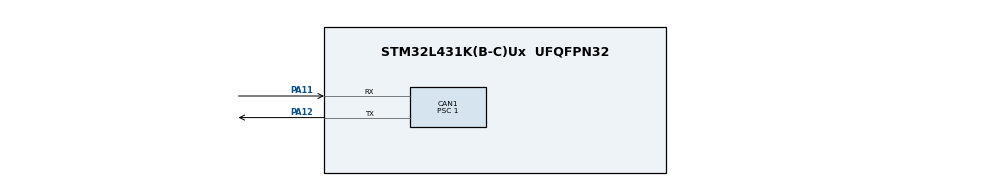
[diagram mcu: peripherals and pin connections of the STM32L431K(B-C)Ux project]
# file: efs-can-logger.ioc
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CAN1.BS1=CAN_BS1_6TQ
CAN1.CalculateBaudRate=500000
CAN1.CalculateTimeBit=2000
CAN1.CalculateTimeQuantum=250.0
CAN1.Prescaler=1
CAN1.SJW=CAN_SJW_2TQ
Mcu.Family=STM32L4
Mcu.Name=STM32L431K(B-C)Ux
Mcu.Package=UFQFPN32
NVIC.CAN1_RX0_IRQn=true\:0\:0\:false\:false\:true\:true\:true\:true
NVIC.PriorityGroup=NVIC_PRIORITYGROUP_4
PA11.GPIO_PuPd=GPIO_PULLUP
PA11.Mode=CAN_Activate
PA11.Signal=CAN1_RX
PA12.Mode=CAN_Activate
PA12.Signal=CAN1_TX
ProjectManager.HeapSize=0x200
ProjectManager.StackSize=0x400
ProjectManager.TargetToolchain=STM32CubeIDE
RCC.HSE_VALUE=8000000
RCC.HSI48_VALUE=48000000
RCC.HSI_VALUE=16000000
RCC.LSE_VALUE=32768
RCC.MSI_VALUE=4000000
RCC.VCOOutputFreq_Value=32000000
board=custom

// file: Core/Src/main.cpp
/* USER CODE BEGIN Header */
/**
  ******************************************************************************
  * @file           : main.c
  * @brief          : Main program body
  ******************************************************************************
  * @attention
  *
  * Copyright (c) 2025 STMicroelectronics.
  * All rights reserved.
  *
  * This software is licensed under terms that can be found in the LICENSE file
  * in the root directory of this software component.
  * If no LICENSE file comes with this software, it is provided AS-IS.
  *
  ******************************************************************************
  */
/* USER CODE END Header */
#include "main.h"

/* USER CODE BEGIN Includes */
#include "drone_can/drone_can.hpp"
#include "debug/debug.hpp"
#include <stdio.h>

/* USER CODE END Includes */

CAN_HandleTypeDef hcan1;

/* USER CODE BEGIN PV */
static constexpr uint8_t NODE_ID = 42;

/* USER CODE END PV */

void SystemClock_Config(void);
static void MX_GPIO_Init(void);
static void MX_CAN1_Init(void);

int main(void)
{

  /* MCU Configuration--------------------------------------------------------*/

  /* Reset of all peripherals, Initializes the Flash interface and the Systick. */
  HAL_Init();

  /* Configure the system clock */
  SystemClock_Config();

  /* Initialize all configured peripherals */
  MX_GPIO_Init();
  MX_CAN1_Init();
  /* USER CODE BEGIN 2 */
  DroneCan::init(&hcan1, NODE_ID);

  /* USER CODE END 2 */

  /* Infinite loop */
  /* USER CODE BEGIN WHILE */
  while (1)
  {
	  DroneCan::update();
    /* USER CODE END WHILE */

    /* USER CODE BEGIN 3 */
	  HAL_Delay(20);
  }
  /* USER CODE END 3 */
}

void SystemClock_Config(void)
{
  RCC_OscInitTypeDef RCC_OscInitStruct = {0};
  RCC_ClkInitTypeDef RCC_ClkInitStruct = {0};

  /** Configure the main internal regulator output voltage
  */
  if (HAL_PWREx_ControlVoltageScaling(PWR_REGULATOR_VOLTAGE_SCALE1) != HAL_OK)
  {
    Error_Handler();
  }

  /** Initializes the RCC Oscillators according to the specified parameters
  * in the RCC_OscInitTypeDef structure.
  */
  RCC_OscInitStruct.OscillatorType = RCC_OSCILLATORTYPE_MSI;
  RCC_OscInitStruct.MSIState = RCC_MSI_ON;
  RCC_OscInitStruct.MSICalibrationValue = 0;
  RCC_OscInitStruct.MSIClockRange = RCC_MSIRANGE_6;
  RCC_OscInitStruct.PLL.PLLState = RCC_PLL_NONE;
  if (HAL_RCC_OscConfig(&RCC_OscInitStruct) != HAL_OK)
  {
    Error_Handler();
  }

  /** Initializes the CPU, AHB and APB buses clocks
  */
  RCC_ClkInitStruct.ClockType = RCC_CLOCKTYPE_HCLK|RCC_CLOCKTYPE_SYSCLK
                              |RCC_CLOCKTYPE_PCLK1|RCC_CLOCKTYPE_PCLK2;
  RCC_ClkInitStruct.SYSCLKSource = RCC_SYSCLKSOURCE_MSI;
  RCC_ClkInitStruct.AHBCLKDivider = RCC_SYSCLK_DIV1;
  RCC_ClkInitStruct.APB1CLKDivider = RCC_HCLK_DIV1;
  RCC_ClkInitStruct.APB2CLKDivider = RCC_HCLK_DIV1;

  if (HAL_RCC_ClockConfig(&RCC_ClkInitStruct, FLASH_LATENCY_0) != HAL_OK)
  {
    Error_Handler();
  }
}

static void MX_CAN1_Init(void)
{

  hcan1.Instance = CAN1;
  hcan1.Init.Prescaler = 1;
  hcan1.Init.Mode = CAN_MODE_NORMAL;
  hcan1.Init.SyncJumpWidth = CAN_SJW_2TQ;
  hcan1.Init.TimeSeg1 = CAN_BS1_6TQ;
  hcan1.Init.TimeSeg2 = CAN_BS2_1TQ;
  hcan1.Init.TimeTriggeredMode = DISABLE;
  hcan1.Init.AutoBusOff = DISABLE;
  hcan1.Init.AutoWakeUp = DISABLE;
  hcan1.Init.AutoRetransmission = DISABLE;
  hcan1.Init.ReceiveFifoLocked = DISABLE;
  hcan1.Init.TransmitFifoPriority = DISABLE;
  if (HAL_CAN_Init(&hcan1) != HAL_OK)
  {
    Error_Handler();
  }

}

static void MX_GPIO_Init(void)
{

  /* GPIO Ports Clock Enable */
  __HAL_RCC_GPIOA_CLK_ENABLE();

}

void Error_Handler(void)
{
  __disable_irq();
  while (1)
  {
  }
}
